# ATSAML22G18A device description
Architecture: CORTEX-M0PLUS; Family: SAML; Series: SAML22
Registers are 32-bit, read-write, reset 0x0 unless marked. A register's access mark holds for its fields unless they carry their own. Offsets are from the block's base; [hi:lo] are bit positions; {n}, {i} and the like mark numbered series; 'fields as' and 'values as' point back to an identical list.

## MTB — Cortex-M0+ Micro-Trace Buffer
Instances: MTB 0x4100A000
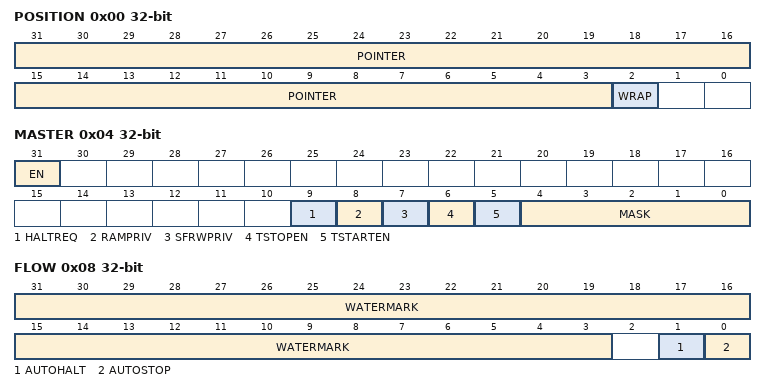
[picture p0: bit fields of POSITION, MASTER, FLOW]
0x00 POSITION reset not defined — MTB Position
  [31:3] POINTER — Trace Packet Location Pointer
  [2] WRAP — Pointer Value Wraps
0x04 MASTER — MTB Master
  [31] EN — Main Trace Enable
  [9] HALTREQ — Halt Request
  [8] RAMPRIV — SRAM Privilege
  [7] SFRWPRIV — Special Function Register Write Privilege
  [6] TSTOPEN — Trace Stop Input Enable
  [5] TSTARTEN — Trace Start Input Enable
  [4:0] MASK — Maximum Value of the Trace Buffer in SRAM
0x08 FLOW — MTB Flow
  [31:3] WATERMARK — Watermark value
  [1] AUTOHALT — Auto Halt Request
  [0] AUTOSTOP — Auto Stop Tracing
0x0C BASE ro reset not defined — MTB Base
0xF00 ITCTRL reset not defined — MTB Integration Mode Control
0xFA0 CLAIMSET reset not defined (atomic set) — MTB Claim Set
0xFA4 CLAIMCLR reset not defined (atomic clear) — MTB Claim Clear
0xFB0 LOCKACCESS reset not defined — MTB Lock Access
0xFB4 LOCKSTATUS ro reset not defined — MTB Lock Status
0xFB8 AUTHSTATUS ro reset not defined — MTB Authentication Status
0xFBC DEVARCH ro reset not defined — MTB Device Architecture
0xFC8 DEVID ro reset not defined — MTB Device Configuration
0xFCC DEVTYPE ro reset not defined — MTB Device Type
{0xFC0+4i} PID{i} ro reset not defined (i=4..7) — Peripheral Identification {i}
{0xFE0+4i} PID{i} ro reset not defined (i=0..3) — Peripheral Identification {i}
{0xFF0+4i} CID{i} ro reset not defined (i=0..3) — Component Identification {i}

## OTP5_FUSES — Non-Volatile Fuses
Instances: OTP5_FUSES 0x00806020 in fuses
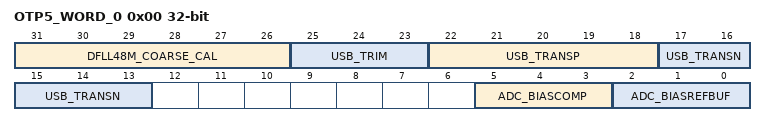
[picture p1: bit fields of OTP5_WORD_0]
0x00 OTP5_WORD_0 ro reset not defined — OTP5 Page Word 0
  [31:26] DFLL48M_COARSE_CAL — DFLL48M Coarse Calibration
  [25:23] USB_TRIM — USB pad Trim calibration
  [22:18] USB_TRANSP — USB pad Transp calibration
  [17:13] USB_TRANSN — USB pad Transn calibration
  [5:3] ADC_BIASCOMP — ADC Comparator Scaling
  [2:0] ADC_BIASREFBUF — ADC Bias Reference Buffer Scaling

## USER_FUSES — Non-Volatile Fuses
Instances: USER_FUSES 0x00804000 in fuses
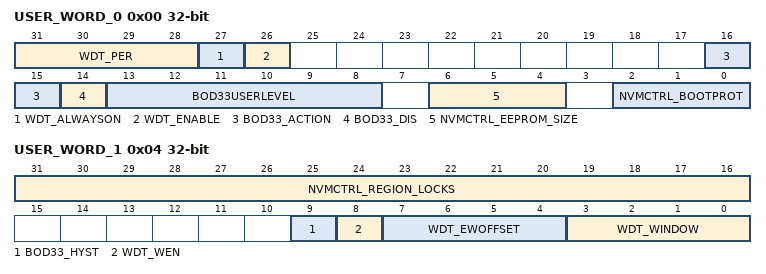
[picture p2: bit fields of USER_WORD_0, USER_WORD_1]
0x00 USER_WORD_0 reset not defined — USER Page Word 0
  [31:28] WDT_PER — WDT Period
    0=CYC8 (8 clock cycles); 1=CYC16 (16 clock cycles); 2=CYC32 (32 clock cycles); 3=CYC64 (64 clock cycles); 4=CYC128 (128 clock cycles); 5=CYC256 (256 clock cycles); 6=CYC512 (512 clock cycles); 7=CYC1024 (1024 clock cycles); 8=CYC2048 (2048 clock cycles); 9=CYC4096 (4096 clock cycles); 10=CYC8192 (8192 clock cycles); 11=CYC16384 (16384 clock cycles)
  [27] WDT_ALWAYSON
  [26] WDT_ENABLE
  [16:15] BOD33_ACTION
    0=NONE (No action); 1=RESET (The BOD33 generates a reset); 2=INT (The BOD33 generates an interrupt); 3=BKUP (The BOD33 puts the device in backup sleep mode)
  [14] BOD33_DIS — BOD33 Disable
  [13:8] BOD33USERLEVEL
  [6:4] NVMCTRL_EEPROM_SIZE — EEPROM Size
    7=0KB (0 kbytes); 6=512B (512 bytes); 5=1KB (1 kbytes); 4=2KB (2 kbytes); 3=4KB (4 kbytes); 2=8KB (8 kbytes); 1=16KB (16 kbytes); 0=32KB (32 kbytes)
  [2:0] NVMCTRL_BOOTPROT — Bootloader Size
    7=0KB (0 bytes); 6=256B (256 bytes); 5=512B (512 bytes); 4=1KB (1 kbytes); 3=2KB (2 kbytes); 2=4KB (4 kbytes); 1=8KB (8 kbytes); 0=16KB (16 kbytes)
0x04 USER_WORD_1 reset not defined — USER Page Word 1
  [31:16] NVMCTRL_REGION_LOCKS — NVM Region Locks
  [9] BOD33_HYST — BOD33 Hysteresis
  [8] WDT_WEN — WDT Window Mode Enable
  [7:4] WDT_EWOFFSET — WDT Early Warning Offset
    values as USER_WORD_0.WDT_PER
  [3:0] WDT_WINDOW
    values as USER_WORD_0.WDT_PER

## OSC32KCTRL — 32k Oscillators Control
Instances: OSC32KCTRL 0x40001400
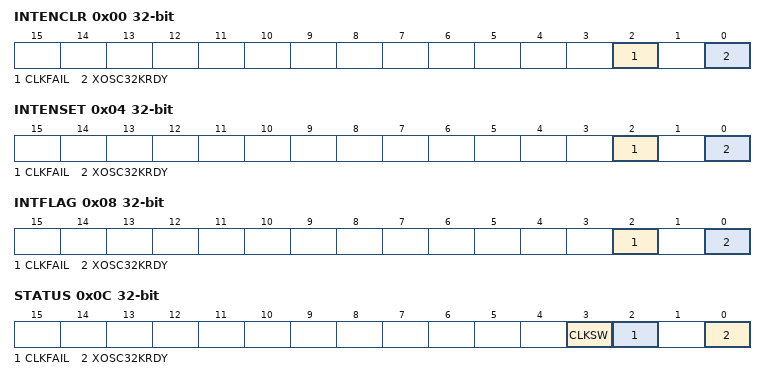
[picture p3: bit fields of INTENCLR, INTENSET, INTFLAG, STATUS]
0x00 INTENCLR (atomic clear) — Interrupt Enable Clear
  [2] CLKFAIL — XOSC32K Clock Failure Detector Interrupt Enable
  [0] XOSC32KRDY — XOSC32K Ready Interrupt Enable
0x04 INTENSET (atomic set) — Interrupt Enable Set
  fields as INTENCLR
0x08 INTFLAG (atomic clear) — Interrupt Flag Status and Clear
  [2] CLKFAIL — XOSC32K Clock Failure Detector
  [0] XOSC32KRDY — XOSC32K Ready
0x0C STATUS ro — Power and Clocks Status
  [3] CLKSW — XOSC32K Clock switch
  [2] CLKFAIL — XOSC32K Clock Failure Detector
  [0] XOSC32KRDY — XOSC32K Ready
0x10 RTCCTRL 8-bit — RTC Clock Selection
  [2:0] RTCSEL
    0=ULP1K (1.024kHz from 32kHz internal ULP oscillator); 1=ULP32K (32.768kHz from 32kHz internal ULP oscillator); 4=XOSC1K (1.024kHz from 32.768kHz external oscillator); 5=XOSC32K (32.768kHz from 32.768kHz external crystal oscillator)
0x11 SLCDCTRL 8-bit — SLCD Clock Selection
  [0] SLCDSEL
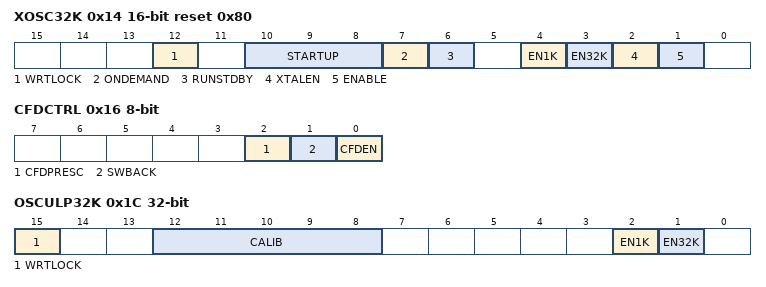
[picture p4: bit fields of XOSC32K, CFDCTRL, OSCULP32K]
0x14 XOSC32K 16-bit reset 0x80 — 32kHz External Crystal Oscillator (XOSC32K) Control
  [12] WRTLOCK — Write Lock
  [10:8] STARTUP — Oscillator Start-Up Time
    0=CYCLE1 (0.122 ms); 1=CYCLE32 (1.068 ms); 2=CYCLE2048 (62.6 ms); 3=CYCLE4096 (125 ms); 4=CYCLE16384 (500 ms); 5=CYCLE32768 (1000 ms); 6=CYCLE65536 (2000 ms); 7=CYCLE131072 (4000 ms)
  [7] ONDEMAND — On Demand Control
  [6] RUNSTDBY — Run in Standby
  [4] EN1K — 1kHz Output Enable
  [3] EN32K — 32kHz Output Enable
  [2] XTALEN — Crystal Oscillator Enable
  [1] ENABLE — Oscillator Enable
0x16 CFDCTRL 8-bit — Clock Failure Detector Control
  [2] CFDPRESC — Clock Failure Detector Prescaler
  [1] SWBACK — Clock Switch Back
  [0] CFDEN — Clock Failure Detector Enable
0x17 EVCTRL 8-bit — Event Control
  [0] CFDEO — Clock Failure Detector Event Output Enable
0x1C OSCULP32K reset not defined — 32kHz Ultra Low Power Internal Oscillator (OSCULP32K) Control
  [15] WRTLOCK — Write Lock
  [12:8] CALIB — Oscillator Calibration
  [2] EN1K — Enable Out 1k
  [1] EN32K — Enable Out 32k

## Notices in the file
Copyright (c) 2018 Microchip Technology Inc.
SPDX-License-Identifier: Apache-2.0
Licensed under the Apache License, Version 2.0 (the "License");
you may not use this file except in compliance with the License.
You may obtain a copy of the License at
http://www.apache.org/licenses/LICENSE-2.0
Unless required by applicable law or agreed to in writing, software
distributed under the License is distributed on an "AS IS" BASIS,
WITHOUT WARRANTIES OR CONDITIONS OF ANY KIND, either express or implied.
See the License for the specific language governing permissions and
limitations under the License.
